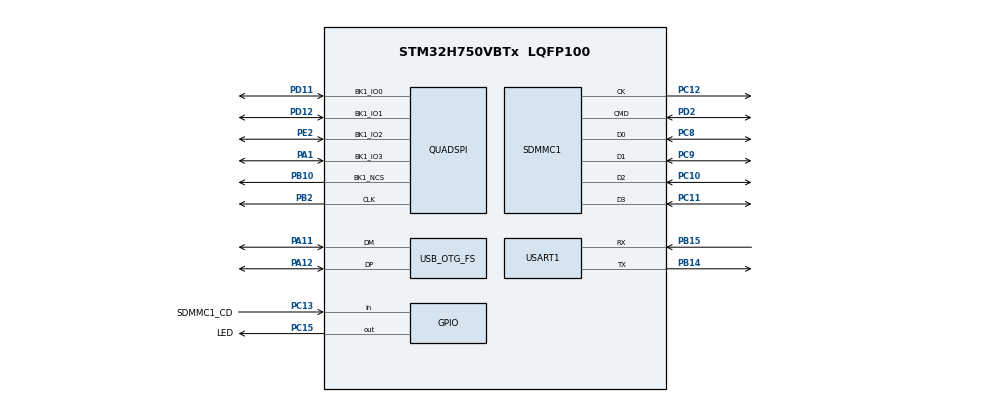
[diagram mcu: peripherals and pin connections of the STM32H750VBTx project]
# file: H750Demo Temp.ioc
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Mcu.Family=STM32H7
Mcu.Name=STM32H750VBTx
Mcu.Package=LQFP100
NVIC.PriorityGroup=NVIC_PRIORITYGROUP_4
PA1.Mode=Single Bank 1
PA1.Signal=QUADSPI_BK1_IO3
PA11.Mode=Device_Only
PA11.Signal=USB_OTG_FS_DM
PA12.Mode=Device_Only
PA12.Signal=USB_OTG_FS_DP
PA13\ (JTMS/SWDIO).Mode=Serial_Wire
PA13\ (JTMS/SWDIO).Signal=DEBUG_JTMS-SWDIO
PA14\ (JTCK/SWCLK).Mode=Serial_Wire
PA14\ (JTCK/SWCLK).Signal=DEBUG_JTCK-SWCLK
PB10.Mode=Single Bank 1
PB10.Signal=QUADSPI_BK1_NCS
PB14.Mode=Asynchronous
PB14.Signal=USART1_TX
PB15.Mode=Asynchronous
PB15.Signal=USART1_RX
PB2.Mode=Single Bank 1
PB2.Signal=QUADSPI_CLK
PC10.Mode=SD_4_bits_Wide_bus
PC10.Signal=SDMMC1_D2
PC11.Mode=SD_4_bits_Wide_bus
PC11.Signal=SDMMC1_D3
PC12.Mode=SD_4_bits_Wide_bus
PC12.Signal=SDMMC1_CK
PC13.GPIO_Label=SDMMC1_CD
PC13.Signal=GPIO_Input
PC15-OSC32_OUT\ (OSC32_OUT).GPIO_Label=LED
PC15-OSC32_OUT\ (OSC32_OUT).Signal=GPIO_Output
PC8.Mode=SD_4_bits_Wide_bus
PC8.Signal=SDMMC1_D0
PC9.Mode=SD_4_bits_Wide_bus
PC9.Signal=SDMMC1_D1
PD11.Mode=Single Bank 1
PD11.Signal=QUADSPI_BK1_IO0
PD12.Mode=Single Bank 1
PD12.Signal=QUADSPI_BK1_IO1
PD2.Mode=SD_4_bits_Wide_bus
PD2.Signal=SDMMC1_CMD
PE2.Mode=Single Bank 1
PE2.Signal=QUADSPI_BK1_IO2
PH0-OSC_IN\ (PH0).Mode=HSE-External-Oscillator
PH0-OSC_IN\ (PH0).Signal=RCC_OSC_IN
PH1-OSC_OUT\ (PH1).Mode=HSE-External-Oscillator
PH1-OSC_OUT\ (PH1).Signal=RCC_OSC_OUT
ProjectManager.HeapSize=0x200
ProjectManager.StackSize=0x400
ProjectManager.TargetToolchain=STM32CubeIDE
QUADSPI.ChipSelectHighTime=QSPI_CS_HIGH_TIME_2_CYCLE
QUADSPI.ClockPrescaler=1
QUADSPI.FifoThreshold=4
QUADSPI.FlashSize=23
RCC.ADCFreq_Value=120000000
RCC.APB1Freq_Value=120000000
RCC.APB2Freq_Value=120000000
RCC.APB3Freq_Value=120000000
RCC.APB4Freq_Value=120000000
RCC.CortexFreq_Value=480000000
RCC.D1PPRE=RCC_APB3_DIV2
RCC.D2PPRE1=RCC_APB1_DIV2
RCC.D2PPRE2=RCC_APB2_DIV2
RCC.D3PPRE=RCC_APB4_DIV2
RCC.DIVM1=1
RCC.DIVM2=1
RCC.DIVN1=120
RCC.DIVN2=30
RCC.DIVQ1=20
RCC.DIVR2=10
RCC.HCLKFreq_Value=240000000
RCC.HPRE=RCC_HCLK_DIV2
RCC.HSE_VALUE=8000000
RCC.PLL2FRACN=0
RCC.PLLFRACN=0
RCC.QSPICLockSelection=RCC_QSPICLKSOURCE_PLL2
RCC.SDMMC1CLockSelection=RCC_SDMMCCLKSOURCE_PLL2
RCC.SYSCLKFreq_VALUE=480000000
RCC.SYSCLKSource=RCC_SYSCLKSOURCE_PLLCLK
RCC.USBFreq_Value=48000000
USART1.VirtualMode-Asynchronous=VM_ASYNC
USB_OTG_FS.VirtualMode=Device_Only
board=custom

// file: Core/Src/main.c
/* USER CODE BEGIN Header */
/**
  ******************************************************************************
  * @file           : main.c
  * @brief          : Main program body
  ******************************************************************************
  * @attention
  *
  * <h2><center>&copy; Copyright (c) 2020 STMicroelectronics.
  * All rights reserved.</center></h2>
  *
  * This software component is licensed by ST under BSD 3-Clause license,
  * the "License"; You may not use this file except in compliance with the
  * License. You may obtain a copy of the License at:
  *                        opensource.org/licenses/BSD-3-Clause
  *
  ******************************************************************************
  */
/* USER CODE END Header */

#include "main.h"
#include "quadspi.h"
#include "sdmmc.h"
#include "usart.h"
#include "usb_otg.h"
#include "gpio.h"

void SystemClock_Config(void);

/* USER CODE BEGIN 0 */
void HAL_SYSTICK_Callback(void)
{
	static int cnt = -100;

	cnt++;
	if(cnt > 500)
	{
		cnt = 0;
		HAL_GPIO_TogglePin(LED_GPIO_Port, LED_Pin);
	}
}
/* USER CODE END 0 */

int main(void)
{

  /* MCU Configuration--------------------------------------------------------*/

  /* Reset of all peripherals, Initializes the Flash interface and the Systick. */
  HAL_Init();

  /* Configure the system clock */
  SystemClock_Config();

  /* Initialize all configured peripherals */
  MX_GPIO_Init();
  MX_QUADSPI_Init();
  MX_SDMMC1_SD_Init();
  MX_USART1_UART_Init();
  MX_USB_OTG_FS_PCD_Init();

  /* Infinite loop */
  while (1)
  {

  }
}

void SystemClock_Config(void)
{
  RCC_OscInitTypeDef RCC_OscInitStruct = {0};
  RCC_ClkInitTypeDef RCC_ClkInitStruct = {0};
  RCC_PeriphCLKInitTypeDef PeriphClkInitStruct = {0};

  /** Supply configuration update enable
  */
  HAL_PWREx_ConfigSupply(PWR_LDO_SUPPLY);
  /** Configure the main internal regulator output voltage
  */
  __HAL_PWR_VOLTAGESCALING_CONFIG(PWR_REGULATOR_VOLTAGE_SCALE0);

  while(!__HAL_PWR_GET_FLAG(PWR_FLAG_VOSRDY)) {}
  /** Macro to configure the PLL clock source
  */
  __HAL_RCC_PLL_PLLSOURCE_CONFIG(RCC_PLLSOURCE_HSE);
  /** Initializes the CPU, AHB and APB busses clocks
  */
  RCC_OscInitStruct.OscillatorType = RCC_OSCILLATORTYPE_HSE;
  RCC_OscInitStruct.HSEState = RCC_HSE_ON;
  RCC_OscInitStruct.PLL.PLLState = RCC_PLL_ON;
  RCC_OscInitStruct.PLL.PLLSource = RCC_PLLSOURCE_HSE;
  RCC_OscInitStruct.PLL.PLLM = 1;
  RCC_OscInitStruct.PLL.PLLN = 120;
  RCC_OscInitStruct.PLL.PLLP = 2;
  RCC_OscInitStruct.PLL.PLLQ = 20;
  RCC_OscInitStruct.PLL.PLLR = 2;
  RCC_OscInitStruct.PLL.PLLRGE = RCC_PLL1VCIRANGE_3;
  RCC_OscInitStruct.PLL.PLLVCOSEL = RCC_PLL1VCOWIDE;
  RCC_OscInitStruct.PLL.PLLFRACN = 0;
  if (HAL_RCC_OscConfig(&RCC_OscInitStruct) != HAL_OK)
  {
    Error_Handler();
  }
  /** Initializes the CPU, AHB and APB busses clocks
  */
  RCC_ClkInitStruct.ClockType = RCC_CLOCKTYPE_HCLK|RCC_CLOCKTYPE_SYSCLK
                              |RCC_CLOCKTYPE_PCLK1|RCC_CLOCKTYPE_PCLK2
                              |RCC_CLOCKTYPE_D3PCLK1|RCC_CLOCKTYPE_D1PCLK1;
  RCC_ClkInitStruct.SYSCLKSource = RCC_SYSCLKSOURCE_PLLCLK;
  RCC_ClkInitStruct.SYSCLKDivider = RCC_SYSCLK_DIV1;
  RCC_ClkInitStruct.AHBCLKDivider = RCC_HCLK_DIV2;
  RCC_ClkInitStruct.APB3CLKDivider = RCC_APB3_DIV2;
  RCC_ClkInitStruct.APB1CLKDivider = RCC_APB1_DIV2;
  RCC_ClkInitStruct.APB2CLKDivider = RCC_APB2_DIV2;
  RCC_ClkInitStruct.APB4CLKDivider = RCC_APB4_DIV2;

  if (HAL_RCC_ClockConfig(&RCC_ClkInitStruct, FLASH_LATENCY_4) != HAL_OK)
  {
    Error_Handler();
  }
  PeriphClkInitStruct.PeriphClockSelection = RCC_PERIPHCLK_USART1|RCC_PERIPHCLK_SDMMC
                              |RCC_PERIPHCLK_USB|RCC_PERIPHCLK_QSPI;
  PeriphClkInitStruct.PLL2.PLL2M = 1;
  PeriphClkInitStruct.PLL2.PLL2N = 30;
  PeriphClkInitStruct.PLL2.PLL2P = 2;
  PeriphClkInitStruct.PLL2.PLL2Q = 2;
  PeriphClkInitStruct.PLL2.PLL2R = 10;
  PeriphClkInitStruct.PLL2.PLL2RGE = RCC_PLL2VCIRANGE_3;
  PeriphClkInitStruct.PLL2.PLL2VCOSEL = RCC_PLL2VCOWIDE;
  PeriphClkInitStruct.PLL2.PLL2FRACN = 0;
  PeriphClkInitStruct.QspiClockSelection = RCC_QSPICLKSOURCE_PLL2;
  PeriphClkInitStruct.SdmmcClockSelection = RCC_SDMMCCLKSOURCE_PLL2;
  PeriphClkInitStruct.Usart16ClockSelection = RCC_USART16CLKSOURCE_D2PCLK2;
  PeriphClkInitStruct.UsbClockSelection = RCC_USBCLKSOURCE_PLL;
  if (HAL_RCCEx_PeriphCLKConfig(&PeriphClkInitStruct) != HAL_OK)
  {
    Error_Handler();
  }
  /** Enable USB Voltage detector
  */
  HAL_PWREx_EnableUSBVoltageDetector();
}

void Error_Handler(void)
{
}

/************************ (C) COPYRIGHT STMicroelectronics *****END OF FILE****/
